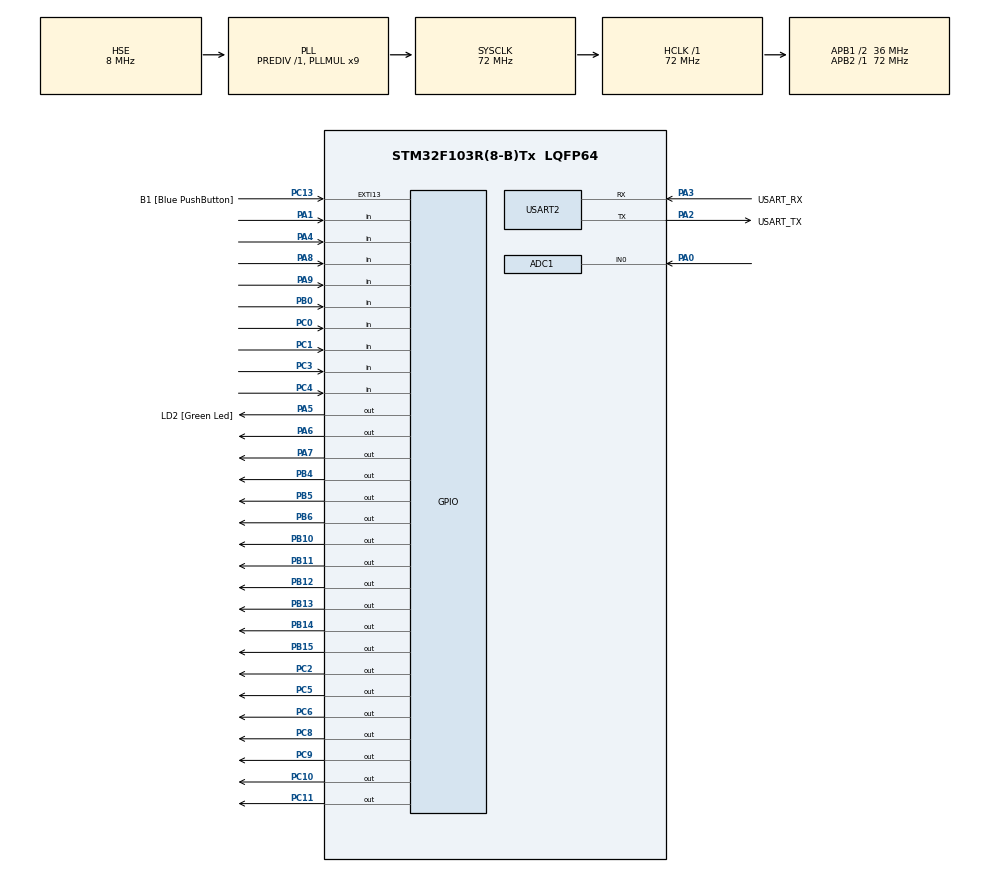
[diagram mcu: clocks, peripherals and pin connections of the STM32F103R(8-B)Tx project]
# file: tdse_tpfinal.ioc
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ADC1.Channel-2\#ChannelRegularConversion=ADC_CHANNEL_0
ADC1.EnableRegularConversion=ENABLE
ADC1.NbrOfConversion=1
ADC1.NbrOfConversionFlag=1
ADC1.Rank-2\#ChannelRegularConversion=1
ADC1.SamplingTime-2\#ChannelRegularConversion=ADC_SAMPLETIME_239CYCLES_5
ADC1.master=1
Mcu.Family=STM32F1
Mcu.Name=STM32F103R(8-B)Tx
Mcu.Package=LQFP64
NVIC.EXTI15_10_IRQn=true\:0\:0\:false\:false\:true\:true\:true\:true
NVIC.PriorityGroup=NVIC_PRIORITYGROUP_4
NVIC.TIM2_IRQn=true\:0\:0\:false\:false\:true\:true\:true\:true
PA0-WKUP.Signal=ADCx_IN0
PA1.GPIO_PuPd=GPIO_PULLDOWN
PA1.Signal=GPIO_Input
PA13.GPIO_Label=TMS
PA13.Mode=Serial_Wire
PA13.Signal=SYS_JTMS-SWDIO
PA14.GPIO_Label=TCK
PA14.Mode=Serial_Wire
PA14.Signal=SYS_JTCK-SWCLK
PA2.GPIO_Label=USART_TX
PA2.GPIO_Mode=GPIO_MODE_AF_PP
PA2.GPIO_PuPd=GPIO_NOPULL
PA2.GPIO_Speed=GPIO_SPEED_FREQ_LOW
PA2.Mode=Asynchronous
PA2.Signal=USART2_TX
PA3.GPIO_Label=USART_RX
PA3.GPIO_Mode=GPIO_MODE_AF_PP
PA3.GPIO_PuPd=GPIO_NOPULL
PA3.GPIO_Speed=GPIO_SPEED_FREQ_LOW
PA3.Mode=Asynchronous
PA3.Signal=USART2_RX
PA4.GPIO_PuPd=GPIO_PULLDOWN
PA4.Signal=GPIO_Input
PA5.GPIO_Label=LD2 [Green Led]
PA5.GPIO_ModeDefaultOutputPP=GPIO_MODE_OUTPUT_PP
PA5.GPIO_PuPd=GPIO_NOPULL
PA5.GPIO_Speed=GPIO_SPEED_FREQ_LOW
PA5.Signal=GPIO_Output
PA6.Signal=GPIO_Output
PA7.Signal=GPIO_Output
PA8.GPIO_PuPd=GPIO_PULLDOWN
PA8.Signal=GPIO_Input
PA9.GPIO_PuPd=GPIO_PULLDOWN
PA9.Signal=GPIO_Input
PB0.Signal=GPIO_Input
PB10.Signal=GPIO_Output
PB11.Signal=GPIO_Output
PB12.Signal=GPIO_Output
PB13.Signal=GPIO_Output
PB14.Signal=GPIO_Output
PB15.Signal=GPIO_Output
PB3.GPIO_Label=SWO
PB3.Signal=SYS_JTDO-TRACESWO
PB4.Signal=GPIO_Output
PB5.Signal=GPIO_Output
PB6.Signal=GPIO_Output
PC0.GPIO_PuPd=GPIO_PULLDOWN
PC0.Signal=GPIO_Input
PC1.Signal=GPIO_Input
PC10.Signal=GPIO_Output
PC11.Signal=GPIO_Output
PC13-TAMPER-RTC.GPIO_Label=B1 [Blue PushButton]
PC13-TAMPER-RTC.GPIO_PuPd=GPIO_NOPULL
PC13-TAMPER-RTC.Signal=GPXTI13
PC14-OSC32_IN.Mode=LSE-External-Oscillator
PC14-OSC32_IN.Signal=RCC_OSC32_IN
PC15-OSC32_OUT.Mode=LSE-External-Oscillator
PC15-OSC32_OUT.Signal=RCC_OSC32_OUT
PC2.Signal=GPIO_Output
PC3.Signal=GPIO_Input
PC4.Signal=GPIO_Input
PC5.Signal=GPIO_Output
PC6.Signal=GPIO_Output
PC8.Signal=GPIO_Output
PC9.Signal=GPIO_Output
PD0-OSC_IN.Mode=HSE-External-Oscillator
PD0-OSC_IN.Signal=RCC_OSC_IN
PD1-OSC_OUT.Mode=HSE-External-Oscillator
PD1-OSC_OUT.Signal=RCC_OSC_OUT
ProjectManager.HeapSize=0x200
ProjectManager.StackSize=0x400
ProjectManager.TargetToolchain=STM32CubeIDE
RCC.ADCPresc=RCC_ADCPCLK2_DIV6
RCC.AHBFreq_Value=72000000
RCC.APB1CLKDivider=RCC_HCLK_DIV2
RCC.APB1Freq_Value=36000000
RCC.APB1TimFreq_Value=72000000
RCC.APB2Freq_Value=72000000
RCC.APB2TimFreq_Value=72000000
RCC.HCLKFreq_Value=72000000
RCC.PLLMUL=RCC_PLL_MUL9
RCC.PLLSourceVirtual=RCC_PLLSOURCE_HSE
RCC.RTCClockSelection=RCC_RTCCLKSOURCE_LSE
RCC.SYSCLKFreq_VALUE=72000000
RCC.SYSCLKSource=RCC_SYSCLKSOURCE_PLLCLK
RCC.USBFreq_Value=72000000
SH.ADCx_IN0.0=ADC1_IN0,IN0
TIM2.Period=999
TIM2.Prescaler=71
USART2.VirtualMode=VM_ASYNC
VP_ADC1_TempSens_Input.Mode=IN-TempSens
VP_TIM2_VS_ClockSourceINT.Mode=Internal
board=NUCLEO-F103RB

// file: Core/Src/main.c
/* USER CODE BEGIN Header */
/**
  ******************************************************************************
  * @file           : main.c
  * @brief          : Main program body
  ******************************************************************************
  * @attention
  *
  * Copyright (c) 2024 STMicroelectronics.
  * All rights reserved.
  *
  * This software is licensed under terms that can be found in the LICENSE file
  * in the root directory of this software component.
  * If no LICENSE file comes with this software, it is provided AS-IS.
  *
  ******************************************************************************
  */
/* USER CODE END Header */
#include "main.h"

/* USER CODE BEGIN Includes */
#include "app.h"
/* USER CODE END Includes */

ADC_HandleTypeDef hadc1;

TIM_HandleTypeDef htim2;

UART_HandleTypeDef huart2;

void SystemClock_Config(void);
static void MX_GPIO_Init(void);
static void MX_USART2_UART_Init(void);
static void MX_ADC1_Init(void);
static void MX_TIM2_Init(void);

/* USER CODE BEGIN 0 */
extern void initialise_monitor_handles(void);
/* USER CODE END 0 */

int main(void)
{

  /* USER CODE BEGIN 1 */
  //initialise_monitor_handles();
  /* USER CODE END 1 */

  /* MCU Configuration--------------------------------------------------------*/

  /* Reset of all peripherals, Initializes the Flash interface and the Systick. */
  HAL_Init();

  /* Configure the system clock */
  SystemClock_Config();

  /* Initialize all configured peripherals */
  MX_GPIO_Init();
  MX_USART2_UART_Init();
  MX_ADC1_Init();
  MX_TIM2_Init();
  /* USER CODE BEGIN 2 */
  app_init();
  /* USER CODE END 2 */

  /* Infinite loop */
  /* USER CODE BEGIN WHILE */
  while (1)
  {
	static uint32_t LastTick = 0;

    /* USER CODE END WHILE */

    /* USER CODE BEGIN 3 */
	if (HAL_GetTick() - LastTick >= 1) // Ejecuta cada 1 milisegundo
	{
		LastTick = HAL_GetTick();
		app_update();
	}
  }
  /* USER CODE END 3 */
}

void SystemClock_Config(void)
{
  RCC_OscInitTypeDef RCC_OscInitStruct = {0};
  RCC_ClkInitTypeDef RCC_ClkInitStruct = {0};
  RCC_PeriphCLKInitTypeDef PeriphClkInit = {0};

  /** Initializes the RCC Oscillators according to the specified parameters
  * in the RCC_OscInitTypeDef structure.
  */
  RCC_OscInitStruct.OscillatorType = RCC_OSCILLATORTYPE_HSE;
  RCC_OscInitStruct.HSEState = RCC_HSE_ON;
  RCC_OscInitStruct.HSEPredivValue = RCC_HSE_PREDIV_DIV1;
  RCC_OscInitStruct.HSIState = RCC_HSI_ON;
  RCC_OscInitStruct.PLL.PLLState = RCC_PLL_ON;
  RCC_OscInitStruct.PLL.PLLSource = RCC_PLLSOURCE_HSE;
  RCC_OscInitStruct.PLL.PLLMUL = RCC_PLL_MUL9;
  if (HAL_RCC_OscConfig(&RCC_OscInitStruct) != HAL_OK)
  {
    Error_Handler();
  }

  /** Initializes the CPU, AHB and APB buses clocks
  */
  RCC_ClkInitStruct.ClockType = RCC_CLOCKTYPE_HCLK|RCC_CLOCKTYPE_SYSCLK
                              |RCC_CLOCKTYPE_PCLK1|RCC_CLOCKTYPE_PCLK2;
  RCC_ClkInitStruct.SYSCLKSource = RCC_SYSCLKSOURCE_PLLCLK;
  RCC_ClkInitStruct.AHBCLKDivider = RCC_SYSCLK_DIV1;
  RCC_ClkInitStruct.APB1CLKDivider = RCC_HCLK_DIV2;
  RCC_ClkInitStruct.APB2CLKDivider = RCC_HCLK_DIV1;

  if (HAL_RCC_ClockConfig(&RCC_ClkInitStruct, FLASH_LATENCY_2) != HAL_OK)
  {
    Error_Handler();
  }
  PeriphClkInit.PeriphClockSelection = RCC_PERIPHCLK_ADC;
  PeriphClkInit.AdcClockSelection = RCC_ADCPCLK2_DIV6;
  if (HAL_RCCEx_PeriphCLKConfig(&PeriphClkInit) != HAL_OK)
  {
    Error_Handler();
  }
}

static void MX_ADC1_Init(void)
{

  ADC_ChannelConfTypeDef sConfig = {0};

  /** Common config
  */
  hadc1.Instance = ADC1;
  hadc1.Init.ScanConvMode = ADC_SCAN_DISABLE;
  hadc1.Init.ContinuousConvMode = DISABLE;
  hadc1.Init.DiscontinuousConvMode = DISABLE;
  hadc1.Init.ExternalTrigConv = ADC_SOFTWARE_START;
  hadc1.Init.DataAlign = ADC_DATAALIGN_RIGHT;
  hadc1.Init.NbrOfConversion = 1;
  if (HAL_ADC_Init(&hadc1) != HAL_OK)
  {
    Error_Handler();
  }

  /** Configure Regular Channel
  */
  sConfig.Channel = ADC_CHANNEL_0;
  sConfig.Rank = ADC_REGULAR_RANK_1;
  sConfig.SamplingTime = ADC_SAMPLETIME_239CYCLES_5;
  if (HAL_ADC_ConfigChannel(&hadc1, &sConfig) != HAL_OK)
  {
    Error_Handler();
  }

}

static void MX_TIM2_Init(void)
{

  TIM_ClockConfigTypeDef sClockSourceConfig = {0};
  TIM_MasterConfigTypeDef sMasterConfig = {0};

  htim2.Instance = TIM2;
  htim2.Init.Prescaler = 71;
  htim2.Init.CounterMode = TIM_COUNTERMODE_UP;
  htim2.Init.Period = 999;
  htim2.Init.ClockDivision = TIM_CLOCKDIVISION_DIV1;
  htim2.Init.AutoReloadPreload = TIM_AUTORELOAD_PRELOAD_DISABLE;
  if (HAL_TIM_Base_Init(&htim2) != HAL_OK)
  {
    Error_Handler();
  }
  sClockSourceConfig.ClockSource = TIM_CLOCKSOURCE_INTERNAL;
  if (HAL_TIM_ConfigClockSource(&htim2, &sClockSourceConfig) != HAL_OK)
  {
    Error_Handler();
  }
  sMasterConfig.MasterOutputTrigger = TIM_TRGO_RESET;
  sMasterConfig.MasterSlaveMode = TIM_MASTERSLAVEMODE_DISABLE;
  if (HAL_TIMEx_MasterConfigSynchronization(&htim2, &sMasterConfig) != HAL_OK)
  {
    Error_Handler();
  }

}

static void MX_USART2_UART_Init(void)
{

  huart2.Instance = USART2;
  huart2.Init.BaudRate = 115200;
  huart2.Init.WordLength = UART_WORDLENGTH_8B;
  huart2.Init.StopBits = UART_STOPBITS_1;
  huart2.Init.Parity = UART_PARITY_NONE;
  huart2.Init.Mode = UART_MODE_TX_RX;
  huart2.Init.HwFlowCtl = UART_HWCONTROL_NONE;
  huart2.Init.OverSampling = UART_OVERSAMPLING_16;
  if (HAL_UART_Init(&huart2) != HAL_OK)
  {
    Error_Handler();
  }

}

static void MX_GPIO_Init(void)
{
  GPIO_InitTypeDef GPIO_InitStruct = {0};
/* USER CODE BEGIN MX_GPIO_Init_1 */
  //__HAL_AFIO_REMAP_SWJ_NOJTAG(); // Deshabilita JTAG pero deja activo SWD (para que poder seguir programando)
/* USER CODE END MX_GPIO_Init_1 */

  /* GPIO Ports Clock Enable */
  __HAL_RCC_GPIOC_CLK_ENABLE();
  __HAL_RCC_GPIOD_CLK_ENABLE();
  __HAL_RCC_GPIOA_CLK_ENABLE();
  __HAL_RCC_GPIOB_CLK_ENABLE();

  /*Configure GPIO pin Output Level */
  HAL_GPIO_WritePin(GPIOC, GPIO_PIN_2|GPIO_PIN_5|GPIO_PIN_6|GPIO_PIN_8
                          |GPIO_PIN_9|GPIO_PIN_10|GPIO_PIN_11, GPIO_PIN_RESET);

  /*Configure GPIO pin Output Level */
  HAL_GPIO_WritePin(GPIOA, LD2_Pin|GPIO_PIN_6|GPIO_PIN_7, GPIO_PIN_RESET);

  /*Configure GPIO pin Output Level */
  HAL_GPIO_WritePin(GPIOB, GPIO_PIN_10|GPIO_PIN_11|GPIO_PIN_12|GPIO_PIN_13
                          |GPIO_PIN_14|GPIO_PIN_15|GPIO_PIN_4|GPIO_PIN_5
                          |GPIO_PIN_6, GPIO_PIN_RESET);

  /*Configure GPIO pin : B1_Pin */
  GPIO_InitStruct.Pin = B1_Pin;
  GPIO_InitStruct.Mode = GPIO_MODE_IT_RISING;
  GPIO_InitStruct.Pull = GPIO_NOPULL;
  HAL_GPIO_Init(B1_GPIO_Port, &GPIO_InitStruct);

  /*Configure GPIO pin : PC0 */
  GPIO_InitStruct.Pin = GPIO_PIN_0;
  GPIO_InitStruct.Mode = GPIO_MODE_INPUT;
  GPIO_InitStruct.Pull = GPIO_PULLDOWN;
  HAL_GPIO_Init(GPIOC, &GPIO_InitStruct);

  /*Configure GPIO pins : PC1 PC3 PC4 */
  GPIO_InitStruct.Pin = GPIO_PIN_1|GPIO_PIN_3|GPIO_PIN_4;
  GPIO_InitStruct.Mode = GPIO_MODE_INPUT;
  GPIO_InitStruct.Pull = GPIO_NOPULL;
  HAL_GPIO_Init(GPIOC, &GPIO_InitStruct);

  /*Configure GPIO pins : PC2 PC5 PC6 PC8
                           PC9 PC10 PC11 */
  GPIO_InitStruct.Pin = GPIO_PIN_2|GPIO_PIN_5|GPIO_PIN_6|GPIO_PIN_8
                          |GPIO_PIN_9|GPIO_PIN_10|GPIO_PIN_11;
  GPIO_InitStruct.Mode = GPIO_MODE_OUTPUT_PP;
  GPIO_InitStruct.Pull = GPIO_NOPULL;
  GPIO_InitStruct.Speed = GPIO_SPEED_FREQ_LOW;
  HAL_GPIO_Init(GPIOC, &GPIO_InitStruct);

  /*Configure GPIO pins : PA1 PA4 PA8 PA9 */
  GPIO_InitStruct.Pin = GPIO_PIN_1|GPIO_PIN_4|GPIO_PIN_8|GPIO_PIN_9;
  GPIO_InitStruct.Mode = GPIO_MODE_INPUT;
  GPIO_InitStruct.Pull = GPIO_PULLDOWN;
  HAL_GPIO_Init(GPIOA, &GPIO_InitStruct);

  /*Configure GPIO pins : LD2_Pin PA6 PA7 */
  GPIO_InitStruct.Pin = LD2_Pin|GPIO_PIN_6|GPIO_PIN_7;
  GPIO_InitStruct.Mode = GPIO_MODE_OUTPUT_PP;
  GPIO_InitStruct.Pull = GPIO_NOPULL;
  GPIO_InitStruct.Speed = GPIO_SPEED_FREQ_LOW;
  HAL_GPIO_Init(GPIOA, &GPIO_InitStruct);

  /*Configure GPIO pin : PB0 */
  GPIO_InitStruct.Pin = GPIO_PIN_0;
  GPIO_InitStruct.Mode = GPIO_MODE_INPUT;
  GPIO_InitStruct.Pull = GPIO_NOPULL;
  HAL_GPIO_Init(GPIOB, &GPIO_InitStruct);

  /*Configure GPIO pins : PB10 PB11 PB12 PB13
                           PB14 PB15 PB4 PB5
                           PB6 */
  GPIO_InitStruct.Pin = GPIO_PIN_10|GPIO_PIN_11|GPIO_PIN_12|GPIO_PIN_13
                          |GPIO_PIN_14|GPIO_PIN_15|GPIO_PIN_4|GPIO_PIN_5
                          |GPIO_PIN_6;
  GPIO_InitStruct.Mode = GPIO_MODE_OUTPUT_PP;
  GPIO_InitStruct.Pull = GPIO_NOPULL;
  GPIO_InitStruct.Speed = GPIO_SPEED_FREQ_LOW;
  HAL_GPIO_Init(GPIOB, &GPIO_InitStruct);

  /* EXTI interrupt init*/
  HAL_NVIC_SetPriority(EXTI15_10_IRQn, 0, 0);
  HAL_NVIC_EnableIRQ(EXTI15_10_IRQn);

}

void Error_Handler(void)
{
  __disable_irq();
  while (1)
  {
  }
}
